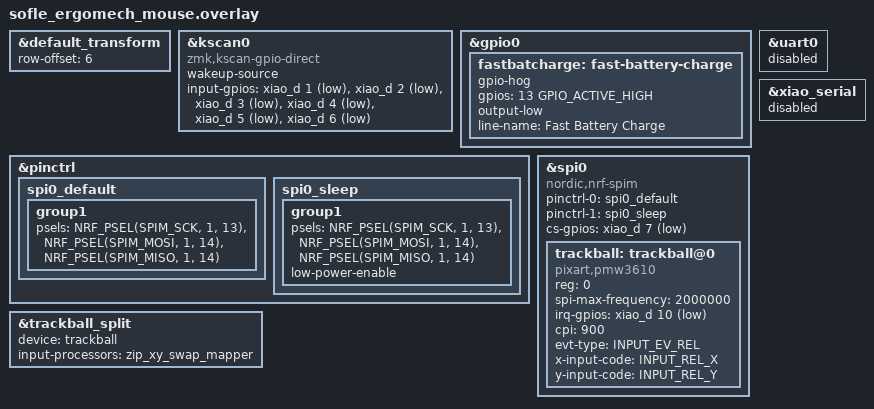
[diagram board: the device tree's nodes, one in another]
/*
 * Copyright (c) 2020 Ryan Cross
 *
 * SPDX-License-Identifier: MIT
 */

#include "sofle_ergomech.dtsi"
#include <dt-bindings/zmk/input_transform.h>
#include <input/processors.dtsi>
#include <dt-bindings/zmk/matrix_transform.h>
#include "trackmouse.dtsi"
#define DEFAULT 0
#define SCRLM 1
#define SCRLH 2
#define DEVICE 3
#define BLTH 4
#define SNIPE 5

&default_transform {
    row-offset = <6>;
};

&kscan0{
    compatible = "zmk,kscan-gpio-direct";
    wakeup-source;
    input-gpios
        = <&xiao_d 1 (GPIO_ACTIVE_LOW | GPIO_PULL_UP)>
        , <&xiao_d 2 (GPIO_ACTIVE_LOW | GPIO_PULL_UP)>
        , <&xiao_d 3 (GPIO_ACTIVE_LOW | GPIO_PULL_UP)>
        , <&xiao_d 4 (GPIO_ACTIVE_LOW | GPIO_PULL_UP)>
        , <&xiao_d 5 (GPIO_ACTIVE_LOW | GPIO_PULL_UP)>
        , <&xiao_d 6 (GPIO_ACTIVE_LOW | GPIO_PULL_UP)>
        ;
};



&gpio0 {
    fastbatcharge: fast-battery-charge {
        gpio-hog;
        gpios = <13 GPIO_ACTIVE_HIGH>;
        output-low;
        line-name = "Fast Battery Charge";
    };
};

&pinctrl {
    spi0_default: spi0_default {
        group1 {
            psels = <NRF_PSEL(SPIM_SCK, 1, 13)>,
                    <NRF_PSEL(SPIM_MOSI, 1, 14)>,
                    <NRF_PSEL(SPIM_MISO, 1, 14)>;
        };
    };

    spi0_sleep: spi0_sleep {
        group1 {
            psels = <NRF_PSEL(SPIM_SCK, 1, 13)>,
                    <NRF_PSEL(SPIM_MOSI, 1, 14)>,
                    <NRF_PSEL(SPIM_MISO, 1, 14)>;
            low-power-enable;
        };
    };
};

&uart0 {
    status = "disabled";
};

&xiao_serial {
    status = "disabled";
};

&spi0 {
    status = "okay";
    compatible = "nordic,nrf-spim";
    pinctrl-0 = <&spi0_default>;
    pinctrl-1 = <&spi0_sleep>;
    pinctrl-names = "default", "sleep";
    cs-gpios = <&xiao_d 7 GPIO_ACTIVE_LOW>;

    trackball: trackball@0 {
        status = "okay";
        compatible = "pixart,pmw3610";
        reg = <0>;
        spi-max-frequency = <2000000>;
        irq-gpios = <&xiao_d 10 (GPIO_ACTIVE_LOW | GPIO_PULL_UP)>;
        cpi = <900>;
        evt-type = <INPUT_EV_REL>;
        x-input-code = <INPUT_REL_X>;
        y-input-code = <INPUT_REL_Y>;
    };
};

&trackball_split {
    device = <&trackball>;
    input-processors = <&zip_xy_swap_mapper>;
};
